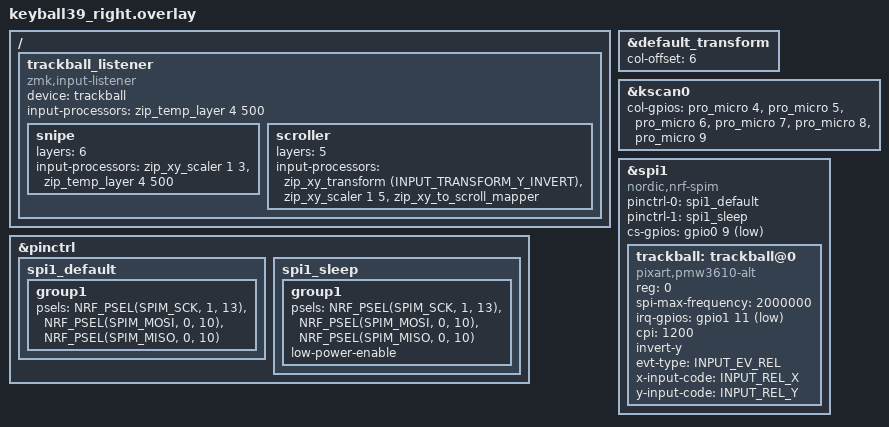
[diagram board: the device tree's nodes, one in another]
/*
 * Copyright (c) 2020 ZMK Contributors
 *
 * SPDX-License-Identifier: MIT
 */

#include "keyball39.dtsi"
#include <zephyr/dt-bindings/input/input-event-codes.h>
#include <input/processors.dtsi>
#include <dt-bindings/zmk/input_transform.h>

&default_transform {
    col-offset = <6>;
};

&kscan0 {
	col-gpios
		= <&pro_micro 4 GPIO_ACTIVE_HIGH>
		, <&pro_micro 5 GPIO_ACTIVE_HIGH>
		, <&pro_micro 6 GPIO_ACTIVE_HIGH>
		, <&pro_micro 7 GPIO_ACTIVE_HIGH>
		, <&pro_micro 8 GPIO_ACTIVE_HIGH>
        , <&pro_micro 9 GPIO_ACTIVE_HIGH>
		;
};

&pinctrl {
    spi1_default: spi1_default {
        group1 {
            psels = <NRF_PSEL(SPIM_SCK, 1, 13)>,
                <NRF_PSEL(SPIM_MOSI, 0, 10)>,
                <NRF_PSEL(SPIM_MISO, 0, 10)>;
        };
    };

    spi1_sleep: spi1_sleep {
        group1 {
            psels = <NRF_PSEL(SPIM_SCK, 1, 13)>,
                <NRF_PSEL(SPIM_MOSI, 0, 10)>,
                <NRF_PSEL(SPIM_MISO, 0, 10)>;
            low-power-enable;
        };
    };
};

&spi1 {
    status = "okay";
    compatible = "nordic,nrf-spim";
    pinctrl-0 = <&spi1_default>;
    pinctrl-1 = <&spi1_sleep>;
    pinctrl-names = "default", "sleep";
    cs-gpios = <&gpio0 9 GPIO_ACTIVE_LOW>;

    trackball: trackball@0 {
        status = "okay";
        compatible = "pixart,pmw3610-alt";
        reg = <0>;
        spi-max-frequency = <2000000>;
        irq-gpios = <&gpio1 11 (GPIO_ACTIVE_LOW | GPIO_PULL_UP)>;
        cpi = <1200>;
        invert-y;
        evt-type = <INPUT_EV_REL>;
        x-input-code = <INPUT_REL_X>;
        y-input-code = <INPUT_REL_Y>;
    };
};

/ {
  trackball_listener {
    compatible = "zmk,input-listener";
    device = <&trackball>;
    input-processors = <&zip_temp_layer 4 500>;

    snipe {
      layers = <6>;
      input-processors = <&zip_xy_scaler 1 3 &zip_temp_layer 4 500>;
    };

    scroller {
      layers = <5>;
      input-processors = <&zip_xy_transform (INPUT_TRANSFORM_Y_INVERT)>, <&zip_xy_scaler 1 5>, <&zip_xy_to_scroll_mapper>;
    };
  };
};
